# M460_v1 register map
File version: 1.0
Registers are 32-bit, read-write, reset 0x0 unless marked. A register's access mark holds for its fields unless they carry their own. Offsets are from the block's base; [hi:lo] are bit positions; {n}, {i} and the like mark numbered series.

## FMC — FMC Register Map
Base 0x4000C000
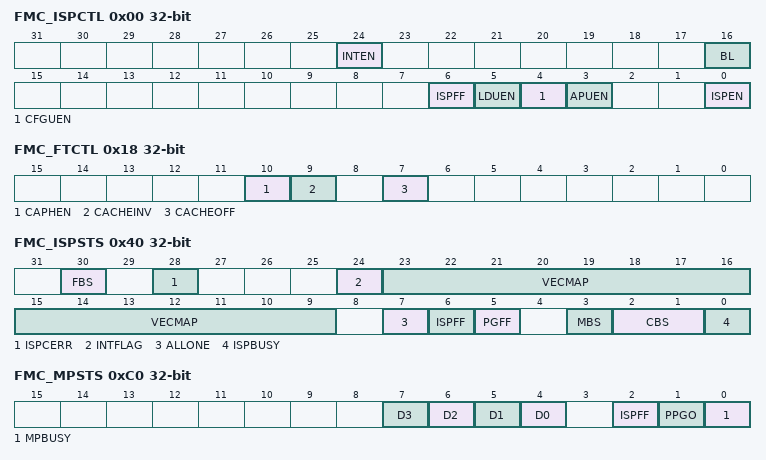
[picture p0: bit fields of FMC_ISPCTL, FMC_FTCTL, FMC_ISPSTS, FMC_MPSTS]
0x00 FMC_ISPCTL — ISP Control Register
  [24] INTEN — Secure ISP INT Enable Bit (Write Protect). Note: This bit is write protected. Refer to the SYS_REGLCTL register. Before using INT, user needs to clear the INTFLAG(FMC_ISPSTS[24]) make sure INT happen at correct time.
    0=ISP INT Disabled; 1=ISP INT Enabled
  [16] BL — Boot Loader Booting (Write Protect). This bit is initiated with the inversed value of MBS (CONFIG0[5]). Any reset, except CPU reset (CPU is 1) or system reset (SYS), BL will be reloaded. This bit is used to check chip boot from Boot Loader or not. User should keep original value of this bit when updating FMC_ISPCTL register. Note: This bit is write protected. Refer to the SYS_REGLCTL register.
    0=Boot from APROM or LDROM; 1=Boot from Boot Loader
  [6] ISPFF — ISP Fail Flag (Write Protect). This bit is set by hardware when a triggered ISP meets any of the following conditions: This bit needs to be cleared by writing 1 to it. APROM writes to itself if APUEN is set to 0. LDROM writes to itself if LDUEN is set to 0. CONFIG is erased/programmed if CFGUEN is set to 0. Erase or Program command at brown-out detected. Destination address is illegal, such as over an available range. Invalid ISP commands. Page Erase command at LOCK mode with ICE connection. Invalid operations (except for chip erase) with ICE connection if KSPLOCK is not 0x5A. Read any content of boot loader with ICE connection. The base and size of new XOM regsions is wrong, overlap or writed twice. The input setting of XOM page erase function is wrong. The active XOM regsion is accessed (except for chip erase, page erase, chksum and read CID/DID). The XOM setting page is accessed (except for chip erase, word program and read). Violate the load code read protection. OTP is erased, multi-word programed or 64-bit read. Checksum or Flash All One Verification is not executed in their valid range. Block erase or bank erase is not executed in APROM. Note: This bit is write protected. Refer to the SYS_REGLCTL register.
  [5] LDUEN — LDROM Update Enable Bit (Write Protect). Note: This bit is write protected. Refer to the SYS_REGLCTL register.
    0=LDROM cannot be updated; 1=LDROM can be updated
  [4] CFGUEN — CONFIG Update Enable Bit (Write Protect). Note: This bit is write protected. Refer to the SYS_REGLCTL register.
    0=CONFIG cannot be updated; 1=CONFIG can be updated
  [3] APUEN — APROM Update Enable Bit (Write Protect). Note: This bit is write protected. Refer to the SYS_REGLCTL register.
    0=APROM cannot be updated when the chip runs in APROM; 1=APROM can be updated when the chip runs in APROM
  [0] ISPEN — ISP Enable Bit (Write Protect). ISP function enable bit. Set this bit to enable ISP function. Note: This bit is write protected. Refer to the SYS_REGLCTL register.
    0=ISP function Disabled; 1=ISP function Enabled
0x04 FMC_ISPADDR — ISP Address Register
  [31:0] ISPADDR — ISP Address. The M460 series is equipped with embedded Flash. ISPADDR[1:0] must be kept 00 for ISP 32-bit operation. ISPADDR[2:0] must be kept 000 for ISP 64-bit operation. For CRC32 Checksum Calculation command, this field is the Flash starting address for checksum calculation, 4 Kbytes alignment is necessary for CRC32 checksum calculation. For Flash32-bit Program, ISP address needs word alignment (4-byte). For Flash 64-bit Program, ISP address needs double word alignment (8-byte).
0x08 FMC_ISPDAT — ISP Data Register
  [31:0] ISPDAT — ISP Data. Write data to this register before ISP program operation. Read data from this register after ISP read operation.
0x0C FMC_ISPCMD — ISP Command Register
  [6:0] CMD — ISP Command. ISP command table is shown below: The other commands are invalid.
    0=FLASH Read; 4=Read Unique ID; 8=Read Flash All-One Result; 11=Read Company ID; 12=Read Device ID; 13=Read Checksum; 33=FLASH 32-bit Program; 34=FLASH Page Erase. Erase any page in two banks, except for OTP; 35=FLASH Bank Erase. Erase all pages of APROM in BANK0 or BANK1; 37=FLASH Block Erase. Erase four pages alignment of APROM in BANK0 or BANK1; 39=FLASH Multi-Word Program; 40=Run Flash All-One Verification; 45=Run Checksum Calculation; 46=Vector Remap; 64=FLASH 64-bit Read; 97=FLASH 64-bit Program
0x10 FMC_ISPTRG — ISP Trigger Control Register
  [0] ISPGO — ISP Start Trigger (Write Protect). Write 1 to start ISP operation and this bit will be cleared to 0 by hardware automatically when ISP operation is finished. Note: This bit is write protected. Refer to the SYS_REGLCTL register.
    0=ISP operation is finished; 1=ISP is progressed
0x14 FMC_DFBA ro reset not defined — Data Flash Base Address
  [31:0] DFBA — Data Flash Base Address. This register indicates Data Flash start address. It is a read only register. The Data Flash is shared with APROM. the content of this register is loaded from CONFIG1
0x18 FMC_FTCTL — Flash Access Time Control Register
  [10] CAPHEN — Flash Cache Prehit Enable (Write Protect). Note: This bit is write protected. Refer to the SYS_REGLCTL register.
    0=Flash Cache Prehit Enable (default); 1=Flash Cache Prehit Disabled
  [9] CACHEINV — Flash Cache Invalidation (Write Protect). Note 1: Write 1 to start cache invalidation. The value will be changed to 0 once the process finishes. Note 2: This bit is write-protected. Refer to the SYS_REGLCTL register.
    0=Flash Cache Invalidation finished (default); 1=Flash Cache Invalidation
  [7] CACHEOFF — Flash Cache Disable Control (Write Protect). Note: This bit is write protected. Refer to the SYS_REGLCTL register.
    0=Flash Cache function Enabled (default); 1=Flash Cache function Disabled
0x40 FMC_ISPSTS — ISP Status Register
  [30] FBS — Flash Bank Selection. This bit indicate which bank is selected to boot.
    0=Booting from BANK0; 1=Booting from BANK1
  [28] ISPCERR — ISP Conflict Error. This bit shows when FMC is doing ISP operation. User cannot access FMC_ISP_ADDR,FMC_ISPDAT,FMC_ISPCMD,FMC_ISPTRG. It would cause ISPFF.
  [24] INTFLAG — ISP Interrupt Flag. Note: This function needs to be enabled by FMC_ISPCTRL[24].
    0=ISP Not Finished; 1=ISP done or ISPFF set
  [23:9] VECMAP ro — Vector Page Mapping Address (Read Only). All access to 0x0000_0000~0x0000_01FF is remapped to the Flash memory address {VECMAP[14:0], 9'h000} ~ {VECMAP[14:0], 9'h1FF}
  [7] ALLONE — Flash All-one Verification Flag. This bit is set by hardware if all of Flash bits are 1, and clear if Flash bits are not all 1 after 'Run Flash All-One Verification' complete; this bit also can be clear by writing 1
    0=All of Flash bits are 1 after 'Run Flash All-One Verification' complete; 1=Flash bits are not all 1 after 'Run Flash All-One Verification' complete
  [6] ISPFF — ISP Fail Flag (Write Protect). This bit is the mirror of ISPFF (FMC_ISPCTL[6]), it needs to be cleared by writing 1 to FMC_ISPCTL[6] or FMC_ISPSTS[6]. This bit is set by hardware when a triggered ISP meets any of the following conditions: APROM writes to itself if APUEN is set to 0. LDROM writes to itself if LDUEN is set to 0. CONFIG is erased/programmed if CFGUEN is set to 0. Erase or Program command at brown-out detected. Destination address is illegal, such as over an available range. Invalid ISP commands. Page Erase command at LOCK mode with ICE connection. Invalid operations (except for chip erase) with ICE connection if KSPLOCK is not 0x5A. Read any content of boot loader with ICE connection. The base and size of new XOM regsions is wrong, overlap or writed twice. The input setting of XOM page erase function is wrong. The active XOM regsion is accessed (except for chip erase, page erase, chksum and read CID/DID). The XOM setting page is accessed (except for chip erase, word program and read). Violate the load code read protection. OTP is erased, multi-word programed or 64-bit read. Checksum or Flash All One Verification is not executed in their valid range. Block erase or bank erase is not executed in APROM. Note: This bit is write protected. Refer to the SYS_REGLCTL register.
  [5] PGFF ro — Flash Program with Fast Verification Flag (Read Only). This bit is set if data is mismatched at ISP programming verification. This bit is clear by performing ISP Flash erase or ISP read CID operation
    0=Flash Program is success; 1=Flash Program is fail. Program data is different with data in the Flash memory
  [3] MBS ro — Boot From Boot Loader Selection Flag (Read Only). This bit is initiated with the MBS (CONFIG0[5]) after any reset is happened except CPU reset (CPU is 1) or system reset (SYS) is happened.
    0=Boot from Boot Loader; 1=Boot from LDROM/APROM.(.see CBS bit setting)
  [2:1] CBS ro — Boot Selection of CONFIG (Read Only). This bit is initiated with the CBS (CONFIG0[7:6]) after any reset is happened except CPU reset (CPU is 1) or system reset (SYS) is happened.
    0=LDROM with IAP mode; 1=LDROM without IAP mode; 2=APROM with IAP mode; 3=APROM without IAP mode
  [0] ISPBUSY ro — ISP Busy Flag (Read Only). Write 1 to start ISP operation and this bit will be cleared to 0 by hardware automatically when ISP operation is finished. This bit is the mirror of ISPGO(FMC_ISPTRG[0]).
    0=ISP operation is finished; 1=ISP is progressed
0x4C FMC_CYCCTL reset 0x1 — Flash Access Cycle Control Register
  [3:0] CYCLE — Flash Access Cycle Control (Write Protect). This register is updated by user before HCLK running in different frequency. The optimized HCLK working frequency range is 176 MHz. Note: This bit is write protected. Refer to the SYS_REGLCTL register.
    1=CPU access with one wait cycle if cache miss; Flash access cycle is 1;; 2=CPU access with two wait cycles if cache miss; Flash access cycle is 2;; 3=CPU access with three wait cycles if cache miss; Flash access cycle is 3;; 4=CPU access with four wait cycles if cache miss; Flash access cycle is 4;; 5=CPU access with five wait cycles if cache miss; Flash access cycle is 5;; 6=CPU access with six wait cycles if cache miss; Flash access cycle is 6;; 7=CPU access with seven wait cycles if cache miss; Flash access cycle is 7;; 8=CPU access with eight wait cycles if cache miss; Flash access cycle is 8;
0x80 FMC_MPDAT0 — ISP Data0 Register
  [31:0] ISPDAT0 — ISP Data 0. This register is the first 32-bit data for 32-bit/64-bit/multi-word programming, and it is also the mirror of FMC_ISPDAT, both registers keep the same data.
0x84 FMC_MPDAT1 — ISP Data1 Register
  [31:0] ISPDAT1 — ISP Data 1. This register is the second 32-bit data for 64-bit/multi-word programming.
0x88 FMC_MPDAT2 — ISP Data2 Register
  [31:0] ISPDAT2 — ISP Data 2. This register is the third 32-bit data for multi-word programming.
0x8C FMC_MPDAT3 — ISP Data3 Register
  [31:0] ISPDAT3 — ISP Data 3. This register is the fourth 32-bit data for multi-word programming.
0xC0 FMC_MPSTS ro — ISP Multi-program Status Register
  [n+4] D{n} (n=0..3) — ISP DATA {n} Flag (Read Only). This bit is set when FMC_MPDAT{n} is written and auto-clear to 0 when the FMC_MPDAT{n} data is programmed to Flash complete.
    0=FMC_MPDAT{n} register is empty, or program to Flash complete; 1=FMC_MPDAT{n} register has been written, and not program to Flash complete
  [2] ISPFF — ISP Fail Flag (Read Only). This bit is the mirror of ISPFF (FMC_ISPCTL[6]). It needs to be cleared by writing 1 to FMC_ISPCTL[6] or FMC_ISPSTS[6]. This bit is set by hardware when a triggered ISP meets any of the following conditions: APROM writes to itself if APUEN is set to 0. LDROM writes to itself if LDUEN is set to 0. CONFIG is erased/programmed if CFGUEN is set to 0. Erase or Program command at brown-out detected. Destination address is illegal, such as over an available range. Invalid ISP commands. Page Erase command at LOCK mode with ICE connection. Read any content of boot loader with ICE connection. The base and size of new XOM regsions is wrong, overlap or writed twice. The input setting of XOM page erase function is wrong. The active XOM regsion is accessed (except for chip erase, page erase, chksum and read CID/DID). The XOM setting page is accessed (except for chip erase, word program and read). Violate the load code read protection. OTP is erased, multi-word programed or 64-bit read. Checksum or Flash All One Verification is not executed in their valid range. Block erase or bank erase is not executed in APROM
  [1] PPGO — ISP Multi-program Status (Read Only)
    0=ISP multi-word program operation is not active; 1=ISP multi-word program operation is in progress
  [0] MPBUSY — ISP Multi-word Program Busy Flag (Read Only). Write 1 to start ISP Multi-Word program operation and this bit will be cleared to 0 by hardware automatically when ISP Multi-Word program operation is finished. This bit is the mirror of ISPGO(FMC_ISPTRG[0]).
    0=ISP Multi-Word program operation is finished; 1=ISP Multi-Word program operation is progressed
0xC4 FMC_MPADDR ro — ISP Multi-program Address Register
  [31:0] MPADDR — ISP Multi-word Program Address. MPADDR is the address of ISP multi-word program operation when ISPGO flag is 1. MPADDR will keep the final ISP address when ISP multi-word program is complete.
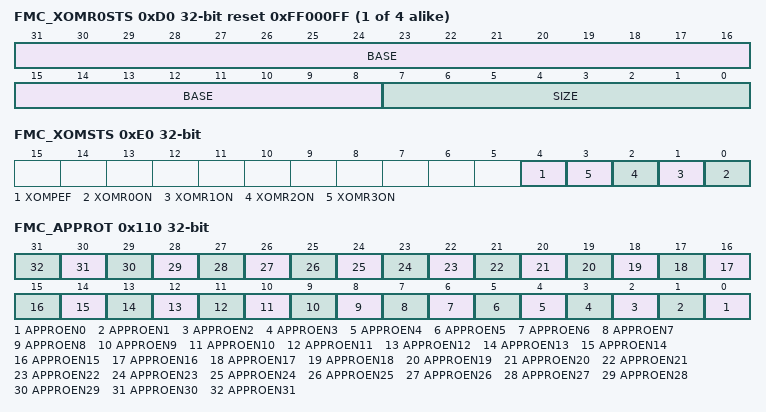
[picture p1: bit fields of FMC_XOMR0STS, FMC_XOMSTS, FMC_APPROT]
{0xD0+4i} FMC_XOMR{i}STS ro reset 0xFF000FF (i=0..3) — XOM Region {i} Status Register
  [31:8] BASE — XOM Region {i} Base Address. BASE is the base address of XOM Region {i}.
  [7:0] SIZE — XOM Region {i} Size. SIZE is the page number of XOM Region {i}.
0xE0 FMC_XOMSTS ro — XOM Status Register
  [4] XOMPEF — XOM Page Erase Function Fail. XOM page erase function status. If XOMPEF is set to 1, user needs to erase XOM region again.
    0=Sucess; 1=Fail
  [n] XOMR{n}ON (n=0..3) — XOM Region {n} On. XOM Region {n} active status.
    0=No active; 1=XOM region {n} is active
0x110 FMC_APPROT — APROM Protect Register
  [all] fields
    0=APROM region n is not protected; 1=APROM region n is protected
  [n] APPROEN{n} (n=0..31) — APROM Proect Enable. This bit indicates which APROM region is protected. Note: APROM protect region is 0x0 + n*(0x8000) to 0x7fff + n*(0x8000)
